# TC37XPD register map
Vendor: Infineon; Series: ATVMC; File version: 100
CPU: other r0p0, little endian, MPU, FPU, vendor SysTick, 4 interrupt priority bits
Registers are 32-bit, read-write, reset 0x0 unless marked. A register's access mark holds for its fields unless they carry their own. Offsets are from the block's base; [hi:lo] are bit positions; {n}, {i} and the like mark numbered series.

## ADMA0 — ADMA
Base 0xF8508400
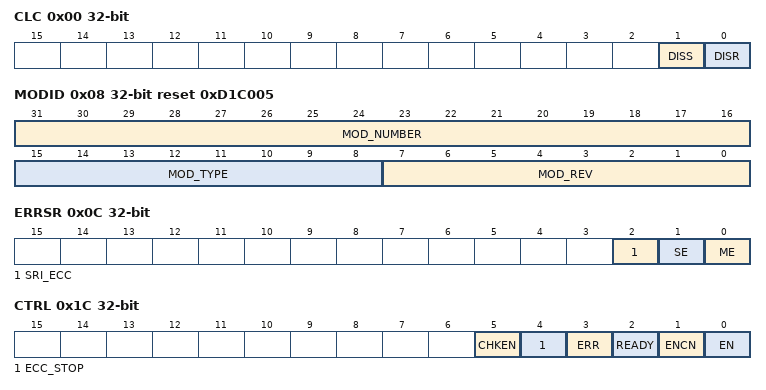
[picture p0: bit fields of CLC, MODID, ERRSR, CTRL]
0x00 CLC access per field — Clock Control Register resetvalue={Application Reset:0x0}
  [1] DISS ro — Module Disable Status Bit DISS. Bit indicates the current status of the module.
  [0] DISR rw — Module Disable Request Bit DISR. Used for enable disable control of the module.
0x08 MODID ro reset 0xD1C005 — Module Identification Register resetvalue={Application Reset:0x0D1C005}
  [31:16] MOD_NUMBER — Module Number Value MOD NUMBER. This bit field defines a module identification number. The value for the AMU is 00D1H.
  [15:8] MOD_TYPE — Module Type MOD TYPE. The bit field is set to C0H which defines the module as a 32 bit module.
  [7:0] MOD_REV — Module Revision Number MOD REV. This bit field defines the module revision number. The value of a module revision starts with 01H first revision .
0x0C ERRSR ro — Error Status Register resetvalue={Application Reset:0x0}
  [2] SRI_ECC — System Memory ECC Error SRI ECC. This error flag is generated by the DMA move engine. An ECC error has been detected in data read from system memory.
  [1] SE — System Error SE. This error flag is generated by the DMA move engine. An error has occurred while reading data from system memory
  [0] ME — Memory Error ME. This error flag is generated by the DMA move engine. An error has occurred while writing to the memory.
0x10 SADR — Source Address Register resetvalue={Application Reset:0x0}
  [31:0] SADR — Source Address Register Pointer SADR. This register contains the source address of the DMA transfer. This is the address from which the DMA engine reads data that is to be transferred. As the value contained by this register must be aligned to an 8 byte boundary bits 2 to 0 must be written with 0 and will always read 0 . A value of 1 written to any of these bits will be ignored
0x14 DADR — Destination Address Register resetvalue={Application Reset:0x0}
  [31:0] DADR — Destination Address Register Pointer DADR. This register contains the destination address of the DMA transfer. This is the address to which the DMA engine writes that data it transfers. As the value contained by this register must be aligned to an 8 byte boundary bits 2 to 0 must be written with 0 and will always read 0 . A value of 1 written to any of these bits will be ignored. As the destination address must always be within the AMU RAM the high order bits not needed to access the AMU memory will cause a memory error if not set to the base address of the AMU RAM. e.g. for a 32 KiB AMU SRAM bits 31 to 15 of the register are the base address and for a 64 KiB AMU SRAM bits 31 to 16 of the register are the base address.
0x18 CNT — Counter Register resetvalue={Application Reset:0x0}
  [31:0] CNT — Byte Counter CNT. This register contains the number of bytes that the DMA engine is about to transfer. As the value contained by this register must be multiples of 8 bits 2 to 0 must be written with 0 and will always read as 0 . A value of 1 written to any of these bits will be ignored. As the destination for a transfer must always be within the AMU RAM the count cannot exceed the size of the RAM. Unneeded bits will be silently ignored. For a 32 KiBAMU SRAM bits 31 to 16 of the register are unneeded and will be silently ignored when written to and will always read 0 . For a 64 KiB AMU SRAM bits 31 to 17 are unneeded and will be silently ignored when written and will always read 0 .
0x1C CTRL access per field — Control Register resetvalue={Application Reset:0x0}
  [5] CHKEN rw — Checksum Enable Mode Bit CHKEN. When set to 1 a cumulative hash value computed from all the data transferred by the ADMA will be stored in the CHKSUM register.
  [4] ECC_STOP rw — ECC Error Mode Bit ECC STOP. When set to 1 a running DMA transfer will be stopped if an ECC error is detected in data read from system memory. When set to 0 the error will still be flagged but the DMA transaction will continue. This type of error is identified by the SRI ECC bit in the ERRSR register.
  [3] ERR ro — Error Interrupt ERR. This flag signifies that an error during the DMA transfer has occurred. An interrupt is raised.
  [2] READY ro — Ready Flag READY. This bit is set by hardware upon successful completion of the DMA transfer.
  [1] ENCN rw — Enable Condition Bit ENCN. If the flag is 0 a change of EN bit is ignored.Read always as 0
  [0] EN rw — Enable Bit EN. Turns on off the engine. Will be cleared when the transfer was stopped or finished. The flag is set while the transfer is running.
0x20 CHKSUM — Checksum Register resetvalue={Application Reset:0x0}
  [31:0] CHKSUM — DATA Checksum CHKSUM. Hash value calculated from all data transferred by the ADMA since the register was last initialised.
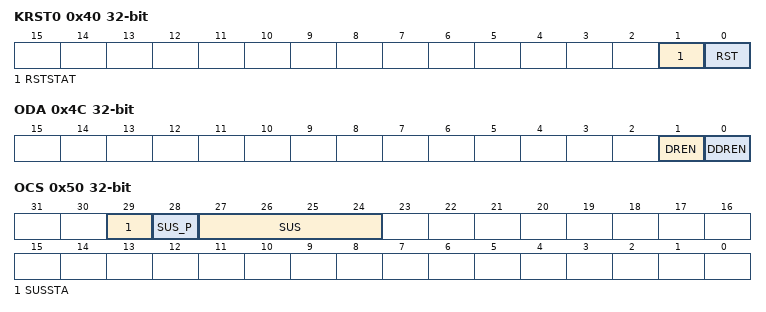
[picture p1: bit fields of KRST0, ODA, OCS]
0x40 KRST0 access per field — Kernel Reset Register 0 resetvalue={Application Reset:0x0}
  [1] RSTSTAT ro — Kernel Reset Status RSTSTAT. This bit indicates whether a kernel reset was executed or not. This bit is set after the execution of a kernel reset in the same clock cycle both reset bits are cleared ADMA KRST0.RST and ADMA KRST1.RST . This bit can be cleared by writing with 1 to the CLR bit in the related KRSTCLR register.
  [0] RST rw — Kernel Reset RST. This reset bit can be used to request for a kernel reset. The kernel reset will be executed if the reset bits of both kernel registers are set. The RST bit will be cleared reset to 0 after the kernel reset is executed.
0x44 KRST1 — Kernel Reset Register 1 resetvalue={Application Reset:0x0}
  [0] RST — Kernel Reset RST. This reset bit can be used to request for a kernel reset. The kernel reset will be executed if the reset bits of both kernel reset registers is set. The RST bit will be cleared re set to 0 after the kernel reset was executed.
0x48 KRSTCLR wo — Kernel Reset Status Clear Register resetvalue={Application Reset:0x0}
  [0] CLR — Kernel Reset Status Clear CLR. Read always as 0 .
0x4C ODA — OCDS Debug Access Register resetvalue={Debug Reset:0x0}
  [1] DREN — Destructive Read Enable DREN. For details see CROSSREFERENCE .
  [0] DDREN — Destructive Debug Read Enable DDREN. For details see CROSSREFERENCE .
0x50 OCS access per field — OCDS Control and Status Register resetvalue={Debug Reset:0x0}
  [29] SUSSTA ro — Suspend State SUSSTA
  [28] SUS_P wo — SUS Write Protection SUS P. SUS is only written when SUS P is 1 otherwise unchanged. Read as 0.
  [27:24] SUS rw — OCDS Suspend Control SUS. Controls the sensitivity to the suspend signal coming from the OCDS Trigger Switch OTGS
